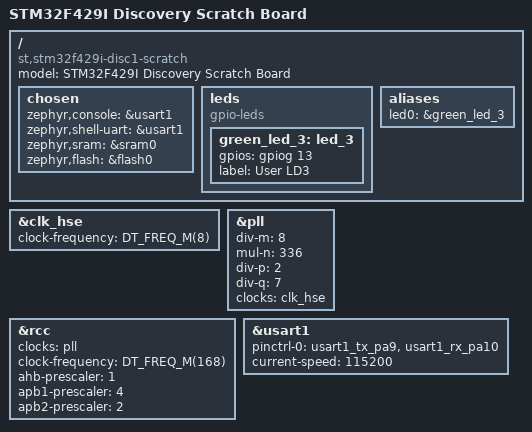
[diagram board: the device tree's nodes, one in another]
/dts-v1/;

#include <st/f4/stm32f429Xi.dtsi>
#include <st/f4/stm32f429zitx-pinctrl.dtsi>
#include <zephyr/dt-bindings/gpio/gpio.h>

/ {
	model = "STM32F429I Discovery Scratch Board";
	compatible = "st,stm32f429i-disc1-scratch";

	chosen {
		zephyr,console = &usart1;
		zephyr,shell-uart = &usart1;
		zephyr,sram = &sram0;
		zephyr,flash = &flash0;
	};

	leds {
		compatible = "gpio-leds";

		green_led_3: led_3 {
			gpios = <&gpiog 13 GPIO_ACTIVE_HIGH>;
			label = "User LD3";
		};
	};

	aliases {
		led0 = &green_led_3;
	};
};

&clk_hse {
	clock-frequency = <DT_FREQ_M(8)>;
	status = "okay";
};

&pll {
	div-m = <8>;
	mul-n = <336>;
	div-p = <2>;
	div-q = <7>;
	clocks = <&clk_hse>;
	status = "okay";
};

&rcc {
	clocks = <&pll>;
	clock-frequency = <DT_FREQ_M(168)>;
	ahb-prescaler = <1>;
	apb1-prescaler = <4>;
	apb2-prescaler = <2>;
};

&usart1 {
	pinctrl-0 = <&usart1_tx_pa9 &usart1_rx_pa10>;
	pinctrl-names = "default";
	current-speed = <115200>;
	status = "okay";
};
